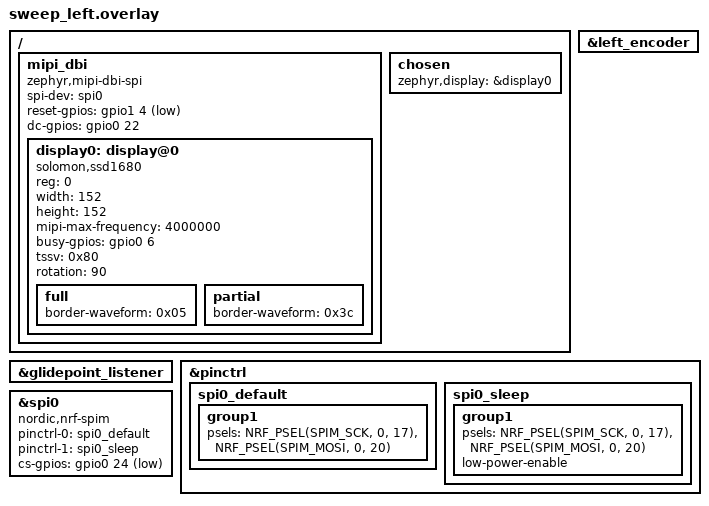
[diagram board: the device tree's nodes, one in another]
#include "sweep.dtsi"

&left_encoder {
	status = "okay";
};

&glidepoint_listener {
    status = "okay";
};


&pinctrl {
	spi0_default: spi0_default {
		group1 {
			/* main role: configure P0.01 as SPI clock, P0.02 as SPI MOSI, P0.03 as SPI MISO */
			psels = <NRF_PSEL(SPIM_SCK, 0, 17)>,
			<NRF_PSEL(SPIM_MOSI, 0, 20)>;
		};
	};
	
	spi0_sleep: spi0_sleep {
		group1 {
			/* main role: configure P0.01 as SPI clock, P0.02 as SPI MOSI, P0.03 as SPI MISO */
			psels = <NRF_PSEL(SPIM_SCK, 0, 17)>,
			<NRF_PSEL(SPIM_MOSI, 0, 20)>;
			low-power-enable;
		};
	};
};

&spi0 {
	status = "okay";
	compatible = "nordic,nrf-spim";
	pinctrl-0 = <&spi0_default>;
	pinctrl-1 = <&spi0_sleep>;
	pinctrl-names = "default", "sleep";
	cs-gpios = <&gpio0 24 GPIO_ACTIVE_LOW>;
};

/ {
	mipi_dbi {
		compatible = "zephyr,mipi-dbi-spi";
		spi-dev = <&spi0>;
		reset-gpios = <&gpio1 4 GPIO_ACTIVE_LOW>;
		dc-gpios = <&gpio0 22 GPIO_ACTIVE_HIGH>;
		#address-cells = <1>;
		#size-cells = <0>;

		display0: display@0 {
			compatible = "solomon,ssd1680";
			status = "okay";
			reg = <0>;
			width = <152>;
			height = <152>;
			mipi-max-frequency = <4000000>;
			busy-gpios = <&gpio0 6 GPIO_ACTIVE_HIGH>;
			tssv = <0x80>;
			rotation = <90>;

			full {
				border-waveform = <0x05>;
			};

			partial {
				border-waveform = <0x3c>;
			};
		};
	};

	chosen {
		zephyr,display = &display0;
	};
};
